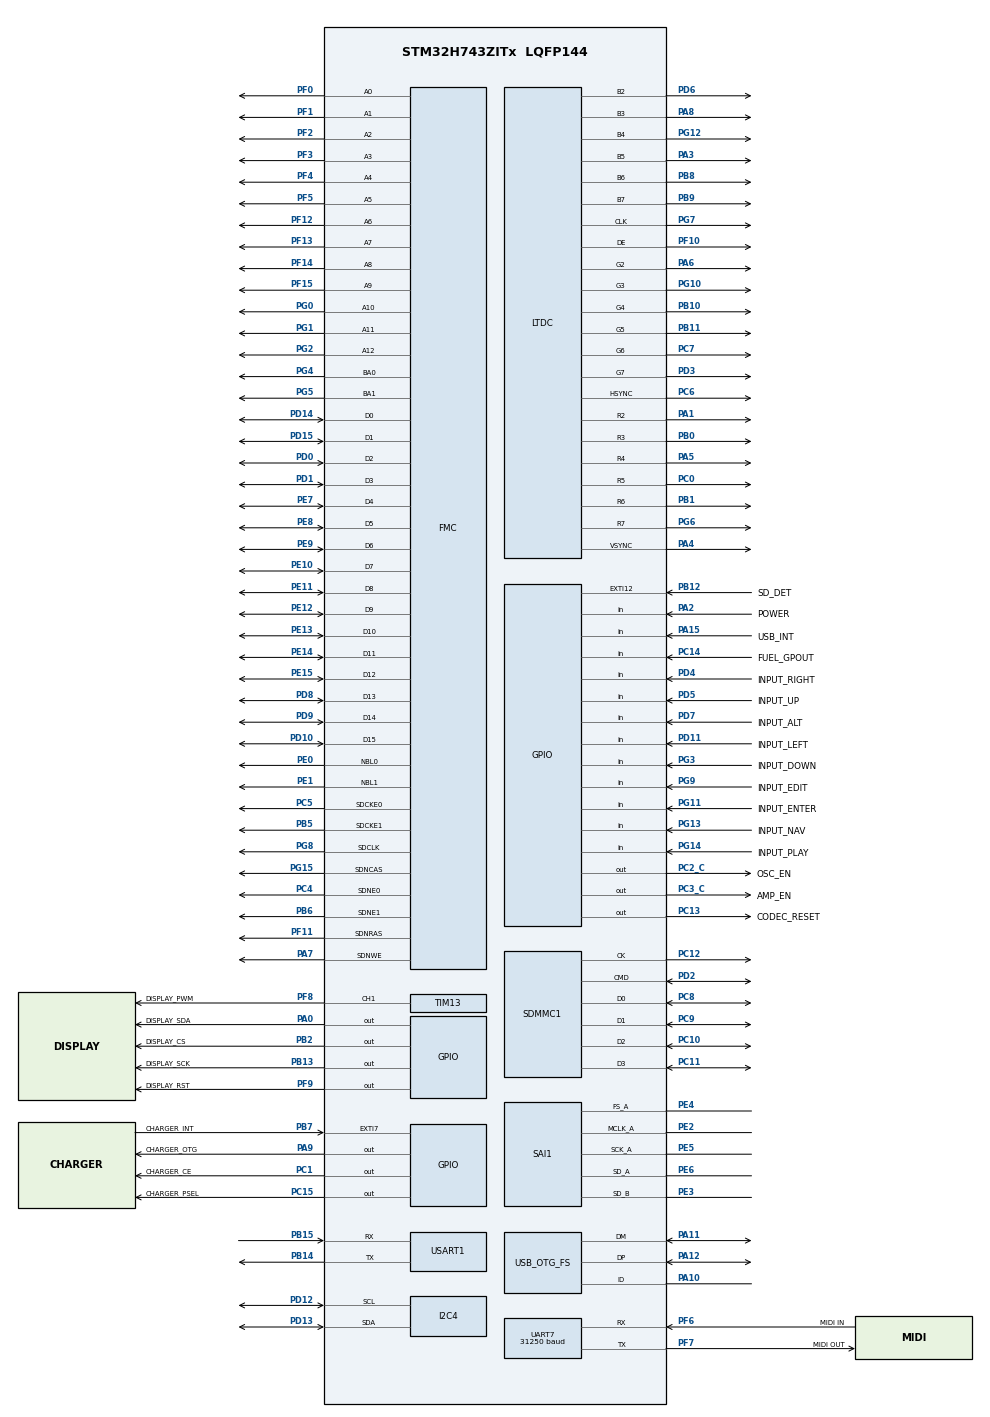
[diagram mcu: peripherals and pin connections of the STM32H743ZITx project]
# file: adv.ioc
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CORTEX_M7.CPU_ICache=Enabled
CORTEX_M7.Enable_Spec=__NULL
CORTEX_M7.default_mode_Activation=1
DMA2D.AlphaModeBackground=DMA2D_REPLACE_ALPHA
DMA2D.AlphaModeForeground=DMA2D_NO_MODIF_ALPHA
DMA2D.ColorMode=DMA2D_OUTPUT_RGB565
DMA2D.InputAlphaBackground=0xff
DMA2D.InputAlphaForeground=0xffff0000
DMA2D.InputColorModeBackground=DMA2D_INPUT_RGB888
DMA2D.InputColorModeForeground=DMA2D_INPUT_A8
DMA2D.InputOffsetBackground=0
DMA2D.Mode=DMA2D_M2M_BLEND_BG
DMA2D.OutputOffset=698
Dma.Request0=SAI1_A
Dma.Request1=SAI1_B
Dma.SAI1_A.0.Direction=DMA_MEMORY_TO_PERIPH
Dma.SAI1_A.0.EventEnable=DISABLE
Dma.SAI1_A.0.FIFOMode=DMA_FIFOMODE_ENABLE
Dma.SAI1_A.0.FIFOThreshold=DMA_FIFO_THRESHOLD_HALFFULL
Dma.SAI1_A.0.Instance=DMA1_Stream0
Dma.SAI1_A.0.MemBurst=DMA_MBURST_SINGLE
Dma.SAI1_A.0.MemDataAlignment=DMA_MDATAALIGN_HALFWORD
Dma.SAI1_A.0.MemInc=DMA_MINC_ENABLE
Dma.SAI1_A.0.Mode=DMA_NORMAL
Dma.SAI1_A.0.PeriphBurst=DMA_PBURST_SINGLE
Dma.SAI1_A.0.PeriphDataAlignment=DMA_PDATAALIGN_HALFWORD
Dma.SAI1_A.0.PeriphInc=DMA_PINC_DISABLE
Dma.SAI1_A.0.Polarity=HAL_DMAMUX_REQ_GEN_RISING
Dma.SAI1_A.0.Priority=DMA_PRIORITY_VERY_HIGH
Dma.SAI1_A.0.RequestNumber=1
Dma.SAI1_A.0.SignalID=NONE
Dma.SAI1_A.0.SyncEnable=DISABLE
Dma.SAI1_A.0.SyncPolarity=HAL_DMAMUX_SYNC_NO_EVENT
Dma.SAI1_A.0.SyncRequestNumber=1
Dma.SAI1_A.0.SyncSignalID=NONE
Dma.SAI1_B.1.Direction=DMA_PERIPH_TO_MEMORY
Dma.SAI1_B.1.EventEnable=DISABLE
Dma.SAI1_B.1.FIFOMode=DMA_FIFOMODE_DISABLE
Dma.SAI1_B.1.Instance=DMA1_Stream1
Dma.SAI1_B.1.MemDataAlignment=DMA_MDATAALIGN_HALFWORD
Dma.SAI1_B.1.MemInc=DMA_MINC_ENABLE
Dma.SAI1_B.1.Mode=DMA_CIRCULAR
Dma.SAI1_B.1.PeriphDataAlignment=DMA_PDATAALIGN_HALFWORD
Dma.SAI1_B.1.PeriphInc=DMA_PINC_DISABLE
Dma.SAI1_B.1.Polarity=HAL_DMAMUX_REQ_GEN_RISING
Dma.SAI1_B.1.Priority=DMA_PRIORITY_HIGH
Dma.SAI1_B.1.RequestNumber=1
Dma.SAI1_B.1.SignalID=NONE
Dma.SAI1_B.1.SyncEnable=DISABLE
Dma.SAI1_B.1.SyncPolarity=HAL_DMAMUX_SYNC_NO_EVENT
Dma.SAI1_B.1.SyncRequestNumber=1
Dma.SAI1_B.1.SyncSignalID=NONE
FMC.CASLatency1=FMC_SDRAM_CAS_LATENCY_3
FMC.CASLatency2=FMC_SDRAM_CAS_LATENCY_3
FMC.ColumnBitsNumber1=FMC_SDRAM_COLUMN_BITS_NUM_9
FMC.ColumnBitsNumber2=FMC_SDRAM_COLUMN_BITS_NUM_9
FMC.ExitSelfRefreshDelay1=7
FMC.ExitSelfRefreshDelay2=7
FMC.LoadToActiveDelay1=4
FMC.LoadToActiveDelay2=4
FMC.RCDDelay1=2
FMC.RCDDelay2=2
FMC.RPDelay1=2
FMC.RPDelay2=2
FMC.ReadBurst1=FMC_SDRAM_RBURST_ENABLE
FMC.ReadBurst2=FMC_SDRAM_RBURST_ENABLE
FMC.RowCycleDelay1=7
FMC.RowCycleDelay2=7
FMC.SDClockPeriod1=FMC_SDRAM_CLOCK_PERIOD_2
FMC.SDClockPeriod2=FMC_SDRAM_CLOCK_PERIOD_2
FMC.SelfRefreshTime1=2
FMC.SelfRefreshTime2=2
FMC.WriteRecoveryTime1=4
FMC.WriteRecoveryTime2=4
LTDC.ActiveH=720
LTDC.ActiveW=720
LTDC.Alpha_L0=255
LTDC.HBP=80
LTDC.HFP=15
LTDC.HSync=5
LTDC.ImageHeight_L0=720
LTDC.ImageWidth_L0=720
LTDC.Layers=0
LTDC.PixelFormat_L0=LTDC_PIXEL_FORMAT_RGB565
LTDC.VBP=20
LTDC.VFP=15
LTDC.VSync=5
LTDC.WindowX1_L0=720
LTDC.WindowY1_L0=720
Mcu.Family=STM32H7
Mcu.Name=STM32H743ZITx
Mcu.Package=LQFP144
NVIC.DMA1_Stream0_IRQn=true\:6\:0\:true\:false\:true\:false\:true\:true
NVIC.DMA1_Stream1_IRQn=true\:6\:0\:true\:false\:true\:false\:true\:true
NVIC.DMA2D_IRQn=true\:0\:0\:false\:false\:true\:true\:true\:true
NVIC.EXTI15_10_IRQn=true\:13\:0\:true\:false\:true\:true\:true\:true
NVIC.EXTI9_5_IRQn=true\:14\:0\:true\:false\:true\:true\:true\:true
NVIC.PriorityGroup=NVIC_PRIORITYGROUP_4
NVIC.SDMMC1_IRQn=true\:3\:0\:true\:false\:true\:true\:true\:true
NVIC.TIM8_UP_TIM13_IRQn=true\:15\:0\:false\:false\:true\:false\:true\:true
NVIC.TimeBase=TIM8_UP_TIM13_IRQn
NVIC.TimeBaseIP=TIM8
NVIC.UART7_IRQn=true\:7\:0\:true\:false\:true\:true\:true\:true
PA0.GPIO_Label=DISPLAY_SDA
PA0.Signal=GPIO_Output
PA1.GPIO_Speed=GPIO_SPEED_FREQ_LOW
PA1.Mode=RGB666
PA1.Signal=LTDC_R2
PA10.Mode=OTG/Dual_Role_Device
PA10.Signal=USB_OTG_FS_ID
PA11.GPIO_Speed=GPIO_SPEED_FREQ_MEDIUM
PA11.Mode=OTG/Dual_Role_Device
PA11.Signal=USB_OTG_FS_DM
PA12.GPIO_Speed=GPIO_SPEED_FREQ_MEDIUM
PA12.Mode=OTG/Dual_Role_Device
PA12.Signal=USB_OTG_FS_DP
PA13\ (JTMS/SWDIO).Mode=Trace_Asynchronous_SW
PA13\ (JTMS/SWDIO).Signal=DEBUG_JTMS-SWDIO
PA14\ (JTCK/SWCLK).Mode=Trace_Asynchronous_SW
PA14\ (JTCK/SWCLK).Signal=DEBUG_JTCK-SWCLK
PA15\ (JTDI).GPIO_Label=USB_INT
PA15\ (JTDI).Signal=GPIO_Input
PA2.GPIO_Label=POWER
PA2.Signal=GPIO_Input
PA3.GPIO_Speed=GPIO_SPEED_FREQ_LOW
PA3.Mode=RGB666
PA3.Signal=LTDC_B5
PA4.GPIO_Speed=GPIO_SPEED_FREQ_LOW
PA4.Mode=RGB666
PA4.Signal=LTDC_VSYNC
PA5.GPIO_Speed=GPIO_SPEED_FREQ_LOW
PA5.Mode=RGB666
PA5.Signal=LTDC_R4
PA6.GPIO_Speed=GPIO_SPEED_FREQ_LOW
PA6.Mode=RGB666
PA6.Signal=LTDC_G2
PA7.GPIO_Speed_High_Default=GPIO_SPEED_FREQ_MEDIUM
PA7.Signal=FMC_SDNWE
PA8.GPIO_Speed=GPIO_SPEED_FREQ_LOW
PA8.Mode=RGB666
PA8.Signal=LTDC_B3
PA9.GPIO_Label=CHARGER_OTG
PA9.Signal=GPIO_Output
PB0.GPIO_Speed=GPIO_SPEED_FREQ_LOW
PB0.Mode=RGB666
PB0.Signal=LTDC_R3
PB1.GPIO_Speed=GPIO_SPEED_FREQ_LOW
PB1.Mode=RGB666
PB1.Signal=LTDC_R6
PB10.GPIO_Speed=GPIO_SPEED_FREQ_LOW
PB10.Mode=RGB666
PB10.Signal=LTDC_G4
PB11.GPIO_Speed=GPIO_SPEED_FREQ_LOW
PB11.Mode=RGB666
PB11.Signal=LTDC_G5
PB12.GPIO_Label=SD_DET
PB12.GPIO_ModeDefaultEXTI=GPIO_MODE_IT_RISING_FALLING
PB12.Signal=GPXTI12
PB13.GPIO_Label=DISPLAY_SCK
PB13.Signal=GPIO_Output
PB14.Mode=Asynchronous
PB14.Signal=USART1_TX
PB15.Mode=Asynchronous
PB15.Signal=USART1_RX
PB2.GPIO_Label=DISPLAY_CS
PB2.Signal=GPIO_Output
PB3\ (JTDO/TRACESWO).Mode=Trace_Asynchronous_SW
PB3\ (JTDO/TRACESWO).Signal=DEBUG_JTDO-SWO
PB4\ (NJTRST).Signal=DEBUG_JTRST
PB5.GPIO_Speed_High_Default=GPIO_SPEED_FREQ_MEDIUM
PB5.Mode=SdramChipSelect2_2
PB5.Signal=FMC_SDCKE1
PB6.GPIO_Speed_High_Default=GPIO_SPEED_FREQ_MEDIUM
PB6.Mode=SdramChipSelect2_2
PB6.Signal=FMC_SDNE1
PB7.GPIO_Label=CHARGER_INT
PB7.GPIO_ModeDefaultEXTI=GPIO_MODE_IT_FALLING
PB7.Signal=GPXTI7
PB8.GPIO_Speed=GPIO_SPEED_FREQ_LOW
PB8.Mode=RGB666
PB8.Signal=LTDC_B6
PB9.GPIO_Speed=GPIO_SPEED_FREQ_LOW
PB9.Mode=RGB666
PB9.Signal=LTDC_B7
PC0.GPIO_Speed=GPIO_SPEED_FREQ_LOW
PC0.Mode=RGB666
PC0.Signal=LTDC_R5
PC1.GPIO_Label=CHARGER_CE
PC1.Signal=GPIO_Output
PC10.Mode=SD_4_bits_Wide_bus
PC10.Signal=SDMMC1_D2
PC11.Mode=SD_4_bits_Wide_bus
PC11.Signal=SDMMC1_D3
PC12.GPIO_Speed_High_Default=GPIO_SPEED_FREQ_MEDIUM
PC12.Mode=SD_4_bits_Wide_bus
PC12.Signal=SDMMC1_CK
PC13.GPIO_Label=CODEC_RESET
PC13.Signal=GPIO_Output
PC14-OSC32_IN\ (OSC32_IN).GPIO_Label=FUEL_GPOUT
PC14-OSC32_IN\ (OSC32_IN).Signal=GPIO_Input
PC15-OSC32_OUT\ (OSC32_OUT).GPIO_Label=CHARGER_PSEL
PC15-OSC32_OUT\ (OSC32_OUT).Signal=GPIO_Output
PC2_C.GPIO_Label=OSC_EN
PC2_C.PinState=GPIO_PIN_SET
PC2_C.Signal=GPIO_Output
PC3_C.GPIO_Label=AMP_EN
PC3_C.PinState=GPIO_PIN_SET
PC3_C.Signal=GPIO_Output
PC4.GPIO_Speed_High_Default=GPIO_SPEED_FREQ_MEDIUM
PC4.Mode=SdramChipSelect1_1
PC4.Signal=FMC_SDNE0
PC5.GPIO_Speed_High_Default=GPIO_SPEED_FREQ_MEDIUM
PC5.Mode=SdramChipSelect1_1
PC5.Signal=FMC_SDCKE0
PC6.GPIO_Speed=GPIO_SPEED_FREQ_LOW
PC6.Mode=RGB666
PC6.Signal=LTDC_HSYNC
PC7.GPIO_Speed=GPIO_SPEED_FREQ_LOW
PC7.Mode=RGB666
PC7.Signal=LTDC_G6
PC8.GPIO_Speed_High_Default=GPIO_SPEED_FREQ_MEDIUM
PC8.Mode=SD_4_bits_Wide_bus
PC8.Signal=SDMMC1_D0
PC9.Mode=SD_4_bits_Wide_bus
PC9.Signal=SDMMC1_D1
PD0.GPIO_Speed_High_Default=GPIO_SPEED_FREQ_MEDIUM
PD0.Signal=FMC_D2_DA2
PD1.GPIO_Speed_High_Default=GPIO_SPEED_FREQ_MEDIUM
PD1.Signal=FMC_D3_DA3
PD10.GPIO_Speed_High_Default=GPIO_SPEED_FREQ_MEDIUM
PD10.Signal=FMC_D15_DA15
PD11.GPIO_Label=INPUT_LEFT
PD11.GPIO_PuPd=GPIO_PULLDOWN
PD11.Signal=GPIO_Input
PD12.Mode=I2C
PD12.Signal=I2C4_SCL
PD13.Mode=I2C
PD13.Signal=I2C4_SDA
PD14.GPIO_Speed_High_Default=GPIO_SPEED_FREQ_MEDIUM
PD14.Signal=FMC_D0_DA0
PD15.GPIO_Speed_High_Default=GPIO_SPEED_FREQ_MEDIUM
PD15.Signal=FMC_D1_DA1
PD2.GPIO_Speed_High_Default=GPIO_SPEED_FREQ_MEDIUM
PD2.Mode=SD_4_bits_Wide_bus
PD2.Signal=SDMMC1_CMD
PD3.GPIO_Speed=GPIO_SPEED_FREQ_LOW
PD3.Mode=RGB666
PD3.Signal=LTDC_G7
PD4.GPIO_Label=INPUT_RIGHT
PD4.GPIO_PuPd=GPIO_PULLDOWN
PD4.Signal=GPIO_Input
PD5.GPIO_Label=INPUT_UP
PD5.GPIO_PuPd=GPIO_PULLDOWN
PD5.Signal=GPIO_Input
PD6.GPIO_Speed=GPIO_SPEED_FREQ_LOW
PD6.Mode=RGB666
PD6.Signal=LTDC_B2
PD7.GPIO_Label=INPUT_ALT
PD7.GPIO_PuPd=GPIO_PULLDOWN
PD7.Signal=GPIO_Input
PD8.GPIO_Speed_High_Default=GPIO_SPEED_FREQ_MEDIUM
PD8.Signal=FMC_D13_DA13
PD9.GPIO_Speed_High_Default=GPIO_SPEED_FREQ_MEDIUM
PD9.Signal=FMC_D14_DA14
PE0.GPIO_Speed_High_Default=GPIO_SPEED_FREQ_MEDIUM
PE0.Signal=FMC_NBL0
PE1.GPIO_Speed_High_Default=GPIO_SPEED_FREQ_MEDIUM
PE1.Signal=FMC_NBL1
PE10.GPIO_Speed_High_Default=GPIO_SPEED_FREQ_MEDIUM
PE10.Signal=FMC_D7_DA7
PE11.GPIO_Speed_High_Default=GPIO_SPEED_FREQ_MEDIUM
PE11.Signal=FMC_D8_DA8
PE12.GPIO_Speed_High_Default=GPIO_SPEED_FREQ_MEDIUM
PE12.Signal=FMC_D9_DA9
PE13.GPIO_Speed_High_Default=GPIO_SPEED_FREQ_MEDIUM
PE13.Signal=FMC_D10_DA10
PE14.GPIO_Speed_High_Default=GPIO_SPEED_FREQ_MEDIUM
PE14.Signal=FMC_D11_DA11
PE15.GPIO_Speed_High_Default=GPIO_SPEED_FREQ_MEDIUM
PE15.Signal=FMC_D12_DA12
PE2.Mode=SAI_A_MasterWithClock
PE2.Signal=SAI1_MCLK_A
PE3.Mode=SAI_B_SyncSlave
PE3.Signal=SAI1_SD_B
PE4.Mode=SAI_A_MasterWithClock
PE4.Signal=SAI1_FS_A
PE5.Mode=SAI_A_MasterWithClock
PE5.Signal=SAI1_SCK_A
PE6.Mode=SAI_A_MasterWithClock
PE6.Signal=SAI1_SD_A
PE7.GPIO_Speed_High_Default=GPIO_SPEED_FREQ_MEDIUM
PE7.Signal=FMC_D4_DA4
PE8.GPIO_Speed_High_Default=GPIO_SPEED_FREQ_MEDIUM
PE8.Signal=FMC_D5_DA5
PE9.GPIO_Speed_High_Default=GPIO_SPEED_FREQ_MEDIUM
PE9.Signal=FMC_D6_DA6
PF0.GPIO_Speed_High_Default=GPIO_SPEED_FREQ_MEDIUM
PF0.Signal=FMC_A0
PF1.GPIO_Speed_High_Default=GPIO_SPEED_FREQ_MEDIUM
PF1.Signal=FMC_A1
PF10.GPIO_Speed=GPIO_SPEED_FREQ_LOW
PF10.Mode=RGB666
PF10.Signal=LTDC_DE
PF11.GPIO_Speed_High_Default=GPIO_SPEED_FREQ_MEDIUM
PF11.Signal=FMC_SDNRAS
PF12.GPIO_Speed_High_Default=GPIO_SPEED_FREQ_MEDIUM
PF12.Signal=FMC_A6
PF13.GPIO_Speed_High_Default=GPIO_SPEED_FREQ_MEDIUM
PF13.Signal=FMC_A7
PF14.GPIO_Speed_High_Default=GPIO_SPEED_FREQ_MEDIUM
PF14.Signal=FMC_A8
PF15.GPIO_Speed_High_Default=GPIO_SPEED_FREQ_MEDIUM
PF15.Signal=FMC_A9
PF2.GPIO_Speed_High_Default=GPIO_SPEED_FREQ_MEDIUM
PF2.Signal=FMC_A2
PF3.GPIO_Speed_High_Default=GPIO_SPEED_FREQ_MEDIUM
PF3.Signal=FMC_A3
PF4.GPIO_Speed_High_Default=GPIO_SPEED_FREQ_MEDIUM
PF4.Signal=FMC_A4
PF5.GPIO_Speed_High_Default=GPIO_SPEED_FREQ_MEDIUM
PF5.Signal=FMC_A5
PF6.GPIO_Label=MIDI IN
PF6.Mode=Asynchronous
PF6.Signal=UART7_RX
PF7.GPIO_Label=MIDI OUT
PF7.Mode=Asynchronous
PF7.Signal=UART7_TX
PF8.GPIO_Label=DISPLAY_PWM
PF8.Signal=S_TIM13_CH1
PF9.GPIO_Label=DISPLAY_RST
PF9.Signal=GPIO_Output
PG0.GPIO_Speed_High_Default=GPIO_SPEED_FREQ_MEDIUM
PG0.Signal=FMC_A10
PG1.GPIO_Speed_High_Default=GPIO_SPEED_FREQ_MEDIUM
PG1.Signal=FMC_A11
PG10.GPIO_Speed=GPIO_SPEED_FREQ_LOW
PG10.Mode=RGB666
PG10.Signal=LTDC_G3
PG11.GPIO_Label=INPUT_ENTER
PG11.GPIO_PuPd=GPIO_PULLDOWN
PG11.Signal=GPIO_Input
PG12.GPIO_Speed=GPIO_SPEED_FREQ_LOW
PG12.Mode=RGB666
PG12.Signal=LTDC_B4
PG13.GPIO_Label=INPUT_NAV
PG13.GPIO_PuPd=GPIO_PULLDOWN
PG13.Signal=GPIO_Input
PG14.GPIO_Label=INPUT_PLAY
PG14.GPIO_PuPd=GPIO_PULLDOWN
PG14.Signal=GPIO_Input
PG15.GPIO_Speed_High_Default=GPIO_SPEED_FREQ_MEDIUM
PG15.Signal=FMC_SDNCAS
PG2.GPIO_Speed_High_Default=GPIO_SPEED_FREQ_MEDIUM
PG2.Signal=FMC_A12
PG3.GPIO_Label=INPUT_DOWN
PG3.GPIO_PuPd=GPIO_PULLDOWN
PG3.Signal=GPIO_Input
PG4.GPIO_Speed_High_Default=GPIO_SPEED_FREQ_MEDIUM
PG4.Signal=FMC_A14_BA0
PG5.GPIO_Speed_High_Default=GPIO_SPEED_FREQ_MEDIUM
PG5.Signal=FMC_A15_BA1
PG6.GPIO_Speed=GPIO_SPEED_FREQ_LOW
PG6.Mode=RGB666
PG6.Signal=LTDC_R7
PG7.GPIO_Speed=GPIO_SPEED_FREQ_MEDIUM
PG7.Mode=RGB666
PG7.Signal=LTDC_CLK
PG8.GPIO_Speed_High_Default=GPIO_SPEED_FREQ_HIGH
PG8.Signal=FMC_SDCLK
PG9.GPIO_Label=INPUT_EDIT
PG9.GPIO_PuPd=GPIO_PULLDOWN
PG9.Signal=GPIO_Input
PH0-OSC_IN\ (PH0).Mode=HSE-External-Oscillator
PH0-OSC_IN\ (PH0).Signal=RCC_OSC_IN
PH1-OSC_OUT\ (PH1).Mode=HSE-External-Oscillator
PH1-OSC_OUT\ (PH1).Signal=RCC_OSC_OUT
ProjectManager.HeapSize=0x200
ProjectManager.StackSize=0x400
ProjectManager.TargetToolchain=CMake
RCC.ADCFreq_Value=56448000
RCC.APB1Freq_Value=119952000
RCC.APB2Freq_Value=119952000
RCC.APB3Freq_Value=119952000
RCC.APB4Freq_Value=119952000
RCC.CKPERSourceSelection=RCC_CLKPSOURCE_HSE
RCC.CortexFreq_Value=479808000
RCC.D1PPRE=RCC_APB3_DIV2
RCC.D2PPRE1=RCC_APB1_DIV2
RCC.D2PPRE2=RCC_APB2_DIV2
RCC.D3PPRE=RCC_APB4_DIV2
RCC.DIVM1=1
RCC.DIVM2=1
RCC.DIVM3=4
RCC.DIVN1=85
RCC.DIVN2=85
RCC.DIVN3=185
RCC.DIVP2=17
RCC.DIVP3=32
RCC.DIVQ1=30
RCC.DIVQ3=32
RCC.DIVR1=24
RCC.DIVR2=8
RCC.DIVR3=14
RCC.FMCCLockSelection=RCC_FMCCLKSOURCE_PLL2
RCC.HCLKFreq_Value=239904000
RCC.HPRE=RCC_HCLK_DIV2
RCC.HSE_VALUE=11289600
RCC.I2C4CLockSelection=RCC_I2C4CLKSOURCE_HSI
RCC.PLL1_VCI_Range-AdvancedSettings=RCC_PLL1VCIRANGE_0
RCC.PLL2FRACN=0
RCC.PLL3FRACN=0
RCC.PLLFRACN=0
RCC.PLLSourceVirtual=RCC_PLLSOURCE_HSE
RCC.SAI1CLockSelection=RCC_SAI1CLKSOURCE_CLKP
RCC.SPI123CLockSelection=RCC_SPI123CLKSOURCE_CLKP
RCC.SYSCLKFreq_VALUE=479808000
RCC.SYSCLKSource=RCC_SYSCLKSOURCE_PLLCLK
RCC.USBCLockSelection=RCC_USBCLKSOURCE_HSI48
RCC.USBFreq_Value=48000000
SAI1.AudioFrequency-SAI_A_MasterWithClock=SAI_AUDIO_FREQUENCY_44K
SAI1.BasicDataSize-SAI_A_MasterWithClock=SAI_PROTOCOL_DATASIZE_16BIT
SAI1.ErrorAudioFreq-SAI_A_MasterWithClock=0.0 %
SAI1.InitProtocol-SAI_A_MasterWithClock=Enable
SAI1.InitProtocol-SAI_B_SyncSlave=Enable
SAI1.Instance-SAI_A_MasterWithClock=SAI$Index_Block_A
SAI1.Instance-SAI_B_SyncSlave=SAI$Index_Block_B
SAI1.MClockEnable-SAI_A_MasterWithClock=SAI_MASTERCLOCK_ENABLE
SAI1.NoDivider-SAI_A_MasterWithClock=SAI_MCK_OVERSAMPLING_DISABLE
SAI1.RealAudioFreq-SAI_A_MasterWithClock=44.1 KHz
SAI1.VirtualMode-SAI_A_MasterWithClock=VM_MASTER
SAI1.VirtualMode-SAI_B_SyncSlave=VM_SLAVE
SAI1.VirtualProtocol-SAI_A_BASIC=VM_BASIC_PROTOCOL
SAI1.VirtualProtocol-SAI_B_BASIC=VM_BASIC_PROTOCOL
SDMMC1.HardwareFlowControl=SDMMC_HARDWARE_FLOW_CONTROL_ENABLE
SH.FMC_A0.0=FMC_A0,13b-sda1
SH.FMC_A0.1=FMC_A0,13b-sda2
SH.FMC_A1.0=FMC_A1,13b-sda1
SH.FMC_A1.1=FMC_A1,13b-sda2
SH.FMC_A10.0=FMC_A10,13b-sda1
SH.FMC_A10.1=FMC_A10,13b-sda2
SH.FMC_A11.0=FMC_A11,13b-sda1
SH.FMC_A11.1=FMC_A11,13b-sda2
SH.FMC_A12.0=FMC_A12,13b-sda1
SH.FMC_A12.1=FMC_A12,13b-sda2
SH.FMC_A14_BA0.0=FMC_BA0,FourSdramBanks1
SH.FMC_A14_BA0.1=FMC_BA0,FourSdramBanks2
SH.FMC_A15_BA1.0=FMC_BA1,FourSdramBanks1
SH.FMC_A15_BA1.1=FMC_BA1,FourSdramBanks2
SH.FMC_A2.0=FMC_A2,13b-sda1
SH.FMC_A2.1=FMC_A2,13b-sda2
SH.FMC_A3.0=FMC_A3,13b-sda1
SH.FMC_A3.1=FMC_A3,13b-sda2
SH.FMC_A4.0=FMC_A4,13b-sda1
SH.FMC_A4.1=FMC_A4,13b-sda2
SH.FMC_A5.0=FMC_A5,13b-sda1
SH.FMC_A5.1=FMC_A5,13b-sda2
SH.FMC_A6.0=FMC_A6,13b-sda1
SH.FMC_A6.1=FMC_A6,13b-sda2
SH.FMC_A7.0=FMC_A7,13b-sda1
SH.FMC_A7.1=FMC_A7,13b-sda2
SH.FMC_A8.0=FMC_A8,13b-sda1
SH.FMC_A8.1=FMC_A8,13b-sda2
SH.FMC_A9.0=FMC_A9,13b-sda1
SH.FMC_A9.1=FMC_A9,13b-sda2
SH.FMC_D0_DA0.0=FMC_D0,sd-16b-d1
SH.FMC_D0_DA0.1=FMC_D0,sd-16b-d2
SH.FMC_D10_DA10.0=FMC_D10,sd-16b-d1
SH.FMC_D10_DA10.1=FMC_D10,sd-16b-d2
SH.FMC_D11_DA11.0=FMC_D11,sd-16b-d1
SH.FMC_D11_DA11.1=FMC_D11,sd-16b-d2
SH.FMC_D12_DA12.0=FMC_D12,sd-16b-d1
SH.FMC_D12_DA12.1=FMC_D12,sd-16b-d2
SH.FMC_D13_DA13.0=FMC_D13,sd-16b-d1
SH.FMC_D13_DA13.1=FMC_D13,sd-16b-d2
SH.FMC_D14_DA14.0=FMC_D14,sd-16b-d1
SH.FMC_D14_DA14.1=FMC_D14,sd-16b-d2
SH.FMC_D15_DA15.0=FMC_D15,sd-16b-d1
SH.FMC_D15_DA15.1=FMC_D15,sd-16b-d2
SH.FMC_D1_DA1.0=FMC_D1,sd-16b-d1
SH.FMC_D1_DA1.1=FMC_D1,sd-16b-d2
SH.FMC_D2_DA2.0=FMC_D2,sd-16b-d1
SH.FMC_D2_DA2.1=FMC_D2,sd-16b-d2
SH.FMC_D3_DA3.0=FMC_D3,sd-16b-d1
SH.FMC_D3_DA3.1=FMC_D3,sd-16b-d2
SH.FMC_D4_DA4.0=FMC_D4,sd-16b-d1
SH.FMC_D4_DA4.1=FMC_D4,sd-16b-d2
SH.FMC_D5_DA5.0=FMC_D5,sd-16b-d1
SH.FMC_D5_DA5.1=FMC_D5,sd-16b-d2
SH.FMC_D6_DA6.0=FMC_D6,sd-16b-d1
SH.FMC_D6_DA6.1=FMC_D6,sd-16b-d2
SH.FMC_D7_DA7.0=FMC_D7,sd-16b-d1
SH.FMC_D7_DA7.1=FMC_D7,sd-16b-d2
SH.FMC_D8_DA8.0=FMC_D8,sd-16b-d1
SH.FMC_D8_DA8.1=FMC_D8,sd-16b-d2
SH.FMC_D9_DA9.0=FMC_D9,sd-16b-d1
SH.FMC_D9_DA9.1=FMC_D9,sd-16b-d2
SH.FMC_NBL0.0=FMC_NBL0,Sd2ByteEnable1
SH.FMC_NBL0.1=FMC_NBL0,Sd2ByteEnable2
SH.FMC_NBL1.0=FMC_NBL1,Sd2ByteEnable1
SH.FMC_NBL1.1=FMC_NBL1,Sd2ByteEnable2
SH.FMC_SDCLK.0=FMC_SDCLK,13b-sda1
SH.FMC_SDCLK.1=FMC_SDCLK,13b-sda2
SH.FMC_SDNCAS.0=FMC_SDNCAS,13b-sda1
SH.FMC_SDNCAS.1=FMC_SDNCAS,13b-sda2
SH.FMC_SDNRAS.0=FMC_SDNRAS,13b-sda1
SH.FMC_SDNRAS.1=FMC_SDNRAS,13b-sda2
SH.FMC_SDNWE.0=FMC_SDNWE,13b-sda1
SH.FMC_SDNWE.1=FMC_SDNWE,13b-sda2
SH.S_TIM13_CH1.0=TIM13_CH1,PWM Generation1 CH1
STMicroelectronics.X-CUBE-ALGOBUILD.1.4.0.LibraryCcDSPOoLibraryJjDSPOoLibrary=true
TIM1.Channel-Output\ Compare1\ No\ Output=TIM_CHANNEL_1
TIM1.Prescaler=480
TIM13.Channel=TIM_CHANNEL_1
TIM13.Period=999
TIM13.Prescaler=239
TIM13.Pulse=500
TIM2.Prescaler=240
UART7.BaudRate=31250
USART1.VirtualMode-Asynchronous=VM_ASYNC
VP_DMA2D_VS_DMA2D.Mode=DMA2D_Activate
VP_MEMORYMAP_VS_MEMORYMAP.Mode=CurAppReg
VP_RNG_VS_RNG.Mode=RNG_Activate
VP_RTC_VS_RTC_Activate.Mode=RTC_Enabled
VP_RTC_VS_RTC_WakeUp_intern.Mode=WakeUp
VP_SAI1_VP_$IpInstance_SAIA_SAI_BASIC.Mode=SAI_A_BASIC
VP_SAI1_VP_$IpInstance_SAIB_SAI_BASIC.Mode=SAI_B_BASIC
VP_STMicroelectronics.X-CUBE-ALGOBUILD_VS_DSPOoLibraryJjLibrary_1.4.0_1.4.0.Mode=DSPOoLibraryJjLibrary
VP_SYS_VS_tim8.Mode=TIM8
VP_TIM13_VS_ClockSourceINT.Mode=Enable_Timer
VP_TIM1_VS_ClockSourceINT.Mode=Internal
VP_TIM1_VS_no_output1.Mode=Output Compare1 No Output
VP_TIM2_VS_ClockSourceINT.Mode=Internal
board=custom

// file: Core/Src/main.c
/* USER CODE BEGIN Header */
/*
 * SPDX-License-Identifier: BSD-3-Clause
 *
 * Copyright (c) 2025
 * STMicroelectronics.
 * Copyright (c) 2025 xiphonics, inc.
 *
 * This file is
 * part of the picoTracker firmware
 */
/* USER CODE END Header */
#include "main.h"
#include "dma.h"
#include "dma2d.h"
#include "fmc.h"
#include "gpio.h"
#include "i2c.h"
#include "ltdc.h"
#include "memorymap.h"
#include "rng.h"
#include "rtc.h"
#include "sai.h"
#include "sdmmc.h"
#include "tim.h"
#include "usart.h"
#include "usb_otg.h"

/* USER CODE BEGIN Includes */
#include "Adapters/adv/system/advSystem.h"
#include "Application/Application.h"
#include "Trace.h"
#include "critical_error_message.h"
#include "display.h"
#include "tusb.h"
#include <cstdio>
/* USER CODE END Includes */

/* USER CODE BEGIN PTD */
__attribute__((section(".firmware_info"))) __attribute__((used))
const firmware_info_t firmware_info = {
    .magic = 0xC0D31355,
    .length = 0,           // placeholder, filled post-link
    .version = 0x62020303, // type, major, minor, patch (type: 0x62: beta,
    // debug: 0x64, 0x72: release)
    .crc32 = 0,        // placeholder, filled post-link
    .type = 0x00006677 // Only two types: "fw" 0x00006677 or "boot" 0x626f6f74
};

/* USER CODE END PTD */

/* USER CODE BEGIN PD */

#ifdef __GNUC__ /* __GNUC__ */
#define PUTCHAR_PROTOTYPE int __io_putchar(int ch)
#else
#define PUTCHAR_PROTOTYPE int fputc(int ch, FILE *f)
#endif /* __GNUC__ */

/* USER CODE END PD */

void SystemClock_Config(void);
void PeriphCommonClock_Config(void);
static void MPU_Config(void);

/* USER CODE BEGIN 0 */
extern uint32_t _sfastcode, _efastcode, _sifastcode;
static void init_fastcode_section(void) {
  uint8_t *fastcode_ram_start = (uint8_t *)&_sfastcode,
          *fastcode_ram_end = (uint8_t *)&_efastcode,
          *fastcode_flash_start = (uint8_t *)&_sifastcode;
  size_t len = fastcode_ram_end - fastcode_ram_start;
  for (size_t i = 0; i < len; i++) {
    *(fastcode_ram_start + i) = *(fastcode_flash_start + i);
  }
}
/* USER CODE END 0 */

int main(void) {

  /* MPU Configuration--------------------------------------------------------*/
  MPU_Config();

  /* Enable the CPU Cache */

  /* Enable I-Cache---------------------------------------------------------*/
  SCB_EnableICache();

  /* MCU Configuration--------------------------------------------------------*/

  /* Reset of all peripherals, Initializes the Flash interface and the Systick.
   */
  HAL_Init();

  /* Configure the system clock */
  SystemClock_Config();

  /* Configure the peripherals common clocks */
  PeriphCommonClock_Config();

  /* Initialize all configured peripherals */
  MX_GPIO_Init();
  MX_DMA_Init();
  MX_FMC_Init();
  MX_I2C4_Init();
  MX_LTDC_Init();
  MX_SAI1_Init();
  MX_SDMMC1_SD_Init();
  MX_UART7_Init();
  MX_USART1_UART_Init();
  MX_TIM1_Init();
  MX_TIM13_Init();
  MX_DMA2D_Init();
  MX_RNG_Init();
  MX_TIM2_Init();
  MX_USB_OTG_FS_USB_Init();
  MX_RTC_Init();
  /* USER CODE BEGIN 2 */

  // Check for EDIT key hold on boot to force load untitled project
  {
    if (HAL_GPIO_ReadPin(INPUT_ENTER_GPIO_Port, INPUT_EDIT_Pin) ==
        GPIO_PIN_SET) {
      forceLoadUntitledProject = true;
    }
  }

  if (SDcardInitError != 0) {
    Trace::Log("MAIN", "SDCARD MISSING!!\n");
    critical_error_message("SDCARD MISSING !", 0x01,
                           DEFAULT_ERROR_MESSAGE_DELAY_SEC, false);
    while (false) {
    }
  }

  // can't use Trace here as its not been initialised yet
  printf("INFO: picoTracker Advance init...");

  init_fastcode_section();

  tusb_rhport_init_t dev_init = {.role = TUSB_ROLE_DEVICE,
                                 .speed = TUSB_SPEED_AUTO};
  tusb_init(0, &dev_init);

  advSystem::Boot();

  GUICreateWindowParams params;
  params.title = "picoTracker Advance";

  Application::GetInstance()->Init(params);

  advSystem::MainLoop();
  // WE NEVER GET HERE

  advSystem::Shutdown();

  /* USER CODE END 2 */

  /* Infinite loop */
  while (1) {

  }
}

void SystemClock_Config(void) {
  RCC_OscInitTypeDef RCC_OscInitStruct = {0};
  RCC_ClkInitTypeDef RCC_ClkInitStruct = {0};

  /** Supply configuration update enable
   */
  HAL_PWREx_ConfigSupply(PWR_LDO_SUPPLY);

  /** Configure the main internal regulator output voltage
   */
  __HAL_PWR_VOLTAGESCALING_CONFIG(PWR_REGULATOR_VOLTAGE_SCALE0);

  while (!__HAL_PWR_GET_FLAG(PWR_FLAG_VOSRDY)) {
  }

  /** Initializes the RCC Oscillators according to the specified parameters
   * in the RCC_OscInitTypeDef structure.
   */
  RCC_OscInitStruct.OscillatorType =
      RCC_OSCILLATORTYPE_HSI48 | RCC_OSCILLATORTYPE_HSI |
      RCC_OSCILLATORTYPE_LSI | RCC_OSCILLATORTYPE_HSE;
  RCC_OscInitStruct.HSEState = RCC_HSE_ON;
  RCC_OscInitStruct.HSIState = RCC_HSI_DIV1;
  RCC_OscInitStruct.HSICalibrationValue = RCC_HSICALIBRATION_DEFAULT;
  RCC_OscInitStruct.LSIState = RCC_LSI_ON;
  RCC_OscInitStruct.HSI48State = RCC_HSI48_ON;
  RCC_OscInitStruct.PLL.PLLState = RCC_PLL_ON;
  RCC_OscInitStruct.PLL.PLLSource = RCC_PLLSOURCE_HSE;
  RCC_OscInitStruct.PLL.PLLM = 1;
  RCC_OscInitStruct.PLL.PLLN = 85;
  RCC_OscInitStruct.PLL.PLLP = 2;
  RCC_OscInitStruct.PLL.PLLQ = 30;
  RCC_OscInitStruct.PLL.PLLR = 24;
  RCC_OscInitStruct.PLL.PLLRGE = RCC_PLL1VCIRANGE_3;
  RCC_OscInitStruct.PLL.PLLVCOSEL = RCC_PLL1VCOWIDE;
  RCC_OscInitStruct.PLL.PLLFRACN = 0;
  if (HAL_RCC_OscConfig(&RCC_OscInitStruct) != HAL_OK) {
    Error_Handler();
  }

  /** Initializes the CPU, AHB and APB buses clocks
   */
  RCC_ClkInitStruct.ClockType = RCC_CLOCKTYPE_HCLK | RCC_CLOCKTYPE_SYSCLK |
                                RCC_CLOCKTYPE_PCLK1 | RCC_CLOCKTYPE_PCLK2 |
                                RCC_CLOCKTYPE_D3PCLK1 | RCC_CLOCKTYPE_D1PCLK1;
  RCC_ClkInitStruct.SYSCLKSource = RCC_SYSCLKSOURCE_PLLCLK;
  RCC_ClkInitStruct.SYSCLKDivider = RCC_SYSCLK_DIV1;
  RCC_ClkInitStruct.AHBCLKDivider = RCC_HCLK_DIV2;
  RCC_ClkInitStruct.APB3CLKDivider = RCC_APB3_DIV2;
  RCC_ClkInitStruct.APB1CLKDivider = RCC_APB1_DIV2;
  RCC_ClkInitStruct.APB2CLKDivider = RCC_APB2_DIV2;
  RCC_ClkInitStruct.APB4CLKDivider = RCC_APB4_DIV2;

  if (HAL_RCC_ClockConfig(&RCC_ClkInitStruct, FLASH_LATENCY_4) != HAL_OK) {
    Error_Handler();
  }
}

void PeriphCommonClock_Config(void) {
  RCC_PeriphCLKInitTypeDef PeriphClkInitStruct = {0};

  /** Initializes the peripherals clock
   */
  PeriphClkInitStruct.PeriphClockSelection = RCC_PERIPHCLK_CKPER;
  PeriphClkInitStruct.CkperClockSelection = RCC_CLKPSOURCE_HSE;
  if (HAL_RCCEx_PeriphCLKConfig(&PeriphClkInitStruct) != HAL_OK) {
    Error_Handler();
  }
}

/* USER CODE BEGIN 4 */

PUTCHAR_PROTOTYPE {
  /* Place your implementation of fputc here */
  /* e.g. write a character to the USART3 and Loop until the end of
             transmission */
  HAL_UART_Transmit(&DEBUG_UART, (uint8_t *)&ch, 1, 0x000F);
  return ch;
}

/* USER CODE END 4 */

/* MPU Configuration */

void MPU_Config(void) {

  /* Disables the MPU */
  HAL_MPU_Disable();

  /* Enables the MPU */
  HAL_MPU_Enable(MPU_PRIVILEGED_DEFAULT);
}

void HAL_TIM_PeriodElapsedCallback(TIM_HandleTypeDef *htim) {
  if (htim->Instance == TIM8) {
    HAL_IncTick();
  }
}

void Error_Handler(void) {
  __disable_irq();
  while (1) {
  }
}

#ifdef USE_FULL_ASSERT
/**
 * @brief  Reports the name of the source file and the source line number
 *         where the assert_param error has occurred.
 * @param  file: pointer to the source file name
 * @param  line: assert_param error line source number
 * @retval None
 */
void assert_failed(uint8_t *file, uint32_t line) {
  /* USER CODE BEGIN 6 */
  /* User can add his own implementation to report the file name and line
     number, ex: printf("Wrong parameters value: file %s on line %d\r\n", file,
     line) */
  /* USER CODE END 6 */
}
#endif /* USE_FULL_ASSERT */
